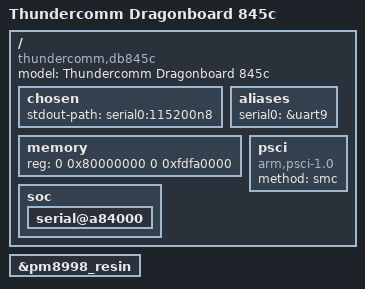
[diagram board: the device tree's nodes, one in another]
// SPDX-License-Identifier: GPL-2.0+
/*
 * Qualcomm Robotics RB3 Development (dragonboard845c) board device
 * tree source
 *
 * (C) Copyright 2022 Sumit Garg <sumit.garg@linaro.org>
 */

/dts-v1/;

#include "sdm845.dtsi"

/ {
	model = "Thundercomm Dragonboard 845c";
	compatible = "thundercomm,db845c", "qcom,sdm845";
	#address-cells = <2>;
	#size-cells = <2>;

	chosen {
		stdout-path = "serial0:115200n8";
	};

	aliases {
		serial0 = &uart9;
	};

	memory {
		device_type = "memory";
		reg = <0 0x80000000 0 0xfdfa0000>;
	};

	psci {
		compatible = "arm,psci-1.0";
		method = "smc";
	};

	soc: soc {
		serial@a84000 {
			status = "okay";
		};
	};
};

&pm8998_resin {
	status = "okay";
};

#include "dragonboard845c-uboot.dtsi"
